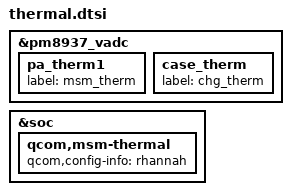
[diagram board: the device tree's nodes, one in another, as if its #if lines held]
#ifndef DEVICE_HANNAH
&pm8937_vadc {
	pa_therm1 {
		label = "msm_therm";
	};

	case_therm {
		label = "chg_therm";
	};
};
#endif

&soc {
	qcom,msm-thermal {
#if defined(DEVICE_RHANNAH)
		qcom,config-info = "rhannah";
#elif defined(DEVICE_HANNAH)
		qcom,config-info = "hannah";
#else
		qcom,config-info = "ahannah";
#endif
	};
};
